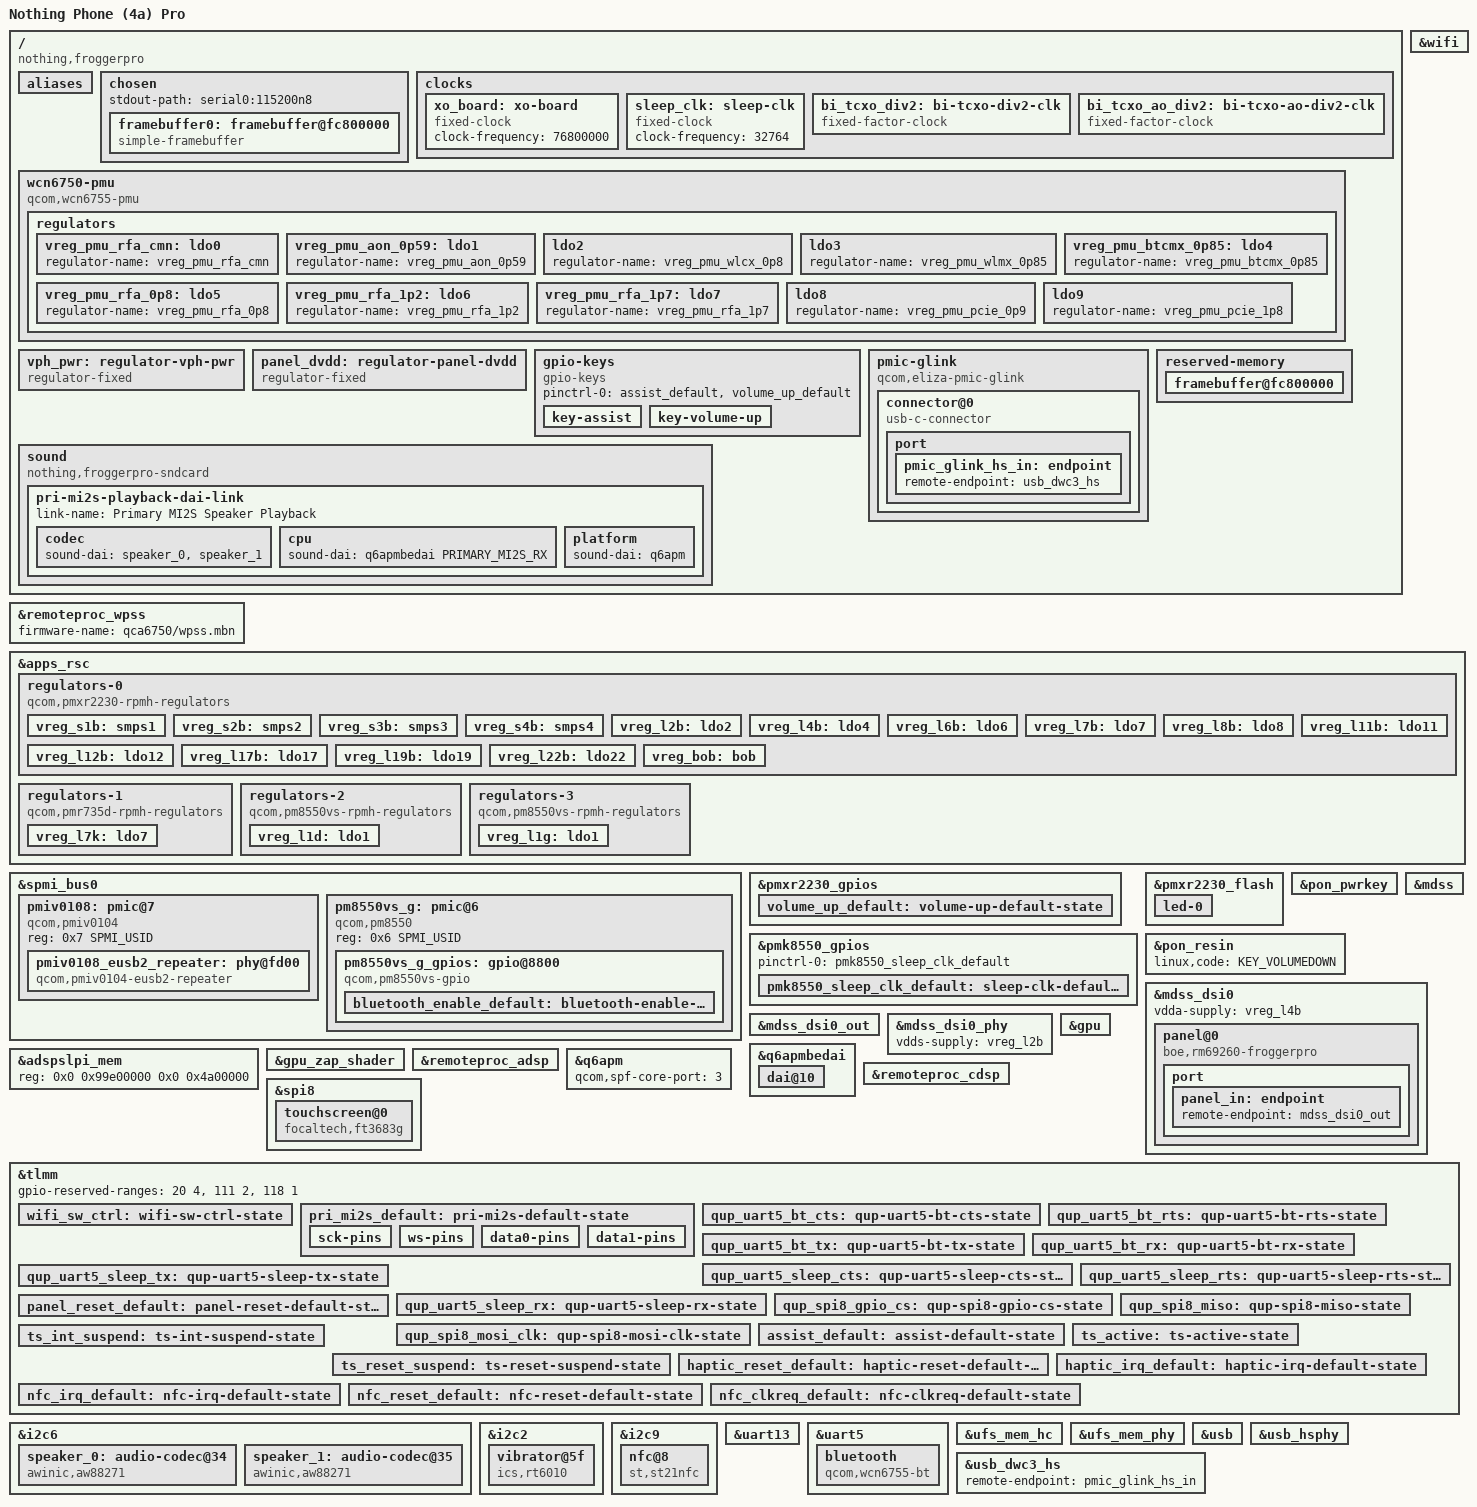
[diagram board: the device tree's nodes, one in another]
// SPDX-License-Identifier: BSD-3-Clause
/*
 * Copyright (c) 2026 Oleksii Onchul <oleksiionchul@gmail.com>
 */

/dts-v1/;

#include <dt-bindings/gpio/gpio.h>
#include <dt-bindings/input/input.h>
#include <dt-bindings/interrupt-controller/irq.h>
#include <dt-bindings/leds/common.h>
#include <dt-bindings/pinctrl/qcom,pmic-gpio.h>
#include <dt-bindings/regulator/qcom,rpmh-regulator.h>
#include <dt-bindings/spmi/spmi.h>

#include "eliza.dtsi"
#include "pmk8550-eliza.dtsi"
#include "pm8550vs-d-eliza.dtsi"
#include "pmr735d-eliza.dtsi"
#include "pmxr2230-eliza.dtsi"

/ {
	model = "Nothing Phone (4a) Pro";
	compatible = "nothing,froggerpro", "qcom,eliza";
	chassis-type = "handset";

	aliases {
		serial0 = &uart13;
		serial1 = &uart5;
	};

	chosen {
		#address-cells = <2>;
		#size-cells = <2>;
		ranges;

		stdout-path = "serial0:115200n8";

		framebuffer0: framebuffer@fc800000 {
			compatible = "simple-framebuffer";
			reg = <0x0 0xfc800000 0x0 (1260 * 2800 * 4)>;
			width = <1260>;
			height = <2800>;
			stride = <(1260 * 4)>;
			format = "a8r8g8b8";

			clocks = <&gcc GCC_DISP_HF_AXI_CLK>,
				 <&dispcc DISP_CC_MDSS_AHB_CLK>,
				 <&dispcc DISP_CC_MDSS_MDP_CLK>,
				 <&dispcc DISP_CC_MDSS_BYTE0_CLK>,
				 <&dispcc DISP_CC_MDSS_BYTE0_INTF_CLK>,
				 <&dispcc DISP_CC_MDSS_PCLK0_CLK>,
				 <&dispcc DISP_CC_MDSS_BYTE1_CLK>,
				 <&dispcc DISP_CC_MDSS_BYTE1_INTF_CLK>,
				 <&dispcc DISP_CC_MDSS_PCLK1_CLK>,
				 <&dispcc DISP_CC_MDSS_VSYNC_CLK>;
			power-domains = <&dispcc MDSS_GDSC>;
		};
	};

	clocks {
		xo_board: xo-board {
			compatible = "fixed-clock";
			clock-frequency = <76800000>;
			#clock-cells = <0>;
		};

		sleep_clk: sleep-clk {
			compatible = "fixed-clock";
			clock-frequency = <32764>;
			#clock-cells = <0>;
		};

		bi_tcxo_div2: bi-tcxo-div2-clk {
			compatible = "fixed-factor-clock";
			#clock-cells = <0>;

			clocks = <&rpmhcc RPMH_CXO_CLK>;
			clock-mult = <1>;
			clock-div = <2>;
		};

		bi_tcxo_ao_div2: bi-tcxo-ao-div2-clk {
			compatible = "fixed-factor-clock";
			#clock-cells = <0>;

			clocks = <&rpmhcc RPMH_CXO_CLK_A>;
			clock-mult = <1>;
			clock-div = <2>;
		};
	};

	wcn6750-pmu {
		compatible = "qcom,wcn6755-pmu", "qcom,wcn6750-pmu";

		vddaon-supply = <&vreg_s3b>;
		vddasd-supply = <&vreg_l7b>;
		vddio-supply = <&vreg_l11b>;
		vddpmu-supply = <&vreg_s3b>;
		vddrfa0p8-supply = <&vreg_s3b>;
		vddrfa1p2-supply = <&vreg_s2b>;
		vddrfa1p7-supply = <&vreg_s1b>;
		vddrfa2p2-supply = <&vreg_s4b>;

		bt-enable-gpios = <&pm8550vs_g_gpios 4 GPIO_ACTIVE_HIGH>;
		clocks = <&rpmhcc RPMH_RF_CLK1>;
		pinctrl-0 = <&bluetooth_enable_default>;
		pinctrl-names = "default";

		regulators {
			vreg_pmu_rfa_cmn: ldo0 {
				regulator-name = "vreg_pmu_rfa_cmn";
			};

			vreg_pmu_aon_0p59: ldo1 {
				regulator-name = "vreg_pmu_aon_0p59";
			};

			ldo2 {
				regulator-name = "vreg_pmu_wlcx_0p8";
			};

			ldo3 {
				regulator-name = "vreg_pmu_wlmx_0p85";
			};

			vreg_pmu_btcmx_0p85: ldo4 {
				regulator-name = "vreg_pmu_btcmx_0p85";
			};

			vreg_pmu_rfa_0p8: ldo5 {
				regulator-name = "vreg_pmu_rfa_0p8";
			};

			vreg_pmu_rfa_1p2: ldo6 {
				regulator-name = "vreg_pmu_rfa_1p2";
			};

			vreg_pmu_rfa_1p7: ldo7 {
				regulator-name = "vreg_pmu_rfa_1p7";
			};

			ldo8 {
				regulator-name = "vreg_pmu_pcie_0p9";
			};

			ldo9 {
				regulator-name = "vreg_pmu_pcie_1p8";
			};
		};
	};

	vph_pwr: regulator-vph-pwr {
		compatible = "regulator-fixed";
		regulator-name = "vph_pwr";
		regulator-min-microvolt = <3700000>;
		regulator-max-microvolt = <3700000>;

		regulator-always-on;
		regulator-boot-on;
	};

	panel_dvdd: regulator-panel-dvdd {
		compatible = "regulator-fixed";
		regulator-name = "panel_dvdd";
		regulator-min-microvolt = <1800000>;
		regulator-max-microvolt = <1800000>;
		gpio = <&tlmm 108 GPIO_ACTIVE_HIGH>;
		enable-active-high;
		regulator-boot-on;
	};

	gpio-keys {
		compatible = "gpio-keys";

		pinctrl-0 = <&assist_default>, <&volume_up_default>;
		pinctrl-names = "default";

		key-assist {
			gpios = <&tlmm 34 GPIO_ACTIVE_LOW>;
			label = "Assistant";
			linux,code = <KEY_LEFTMETA>;
		};

		key-volume-up {
			gpios = <&pmxr2230_gpios 6 GPIO_ACTIVE_LOW>;
			label = "Volume Up";
			linux,code = <KEY_VOLUMEUP>;
		};
	};

	pmic-glink {
		compatible = "qcom,eliza-pmic-glink",
			     "qcom,sm8550-pmic-glink",
			     "qcom,pmic-glink";
		#address-cells = <1>;
		#size-cells = <0>;

		connector@0 {
			compatible = "usb-c-connector";
			reg = <0>;
			data-role = "dual";
			power-role = "dual";

			port {
				pmic_glink_hs_in: endpoint {
					remote-endpoint = <&usb_dwc3_hs>;
				};
			};
		};
	};

	reserved-memory {
		framebuffer@fc800000 {
			reg = <0x0 0xfc800000 0x0 (1260 * 2800 * 4)>;
			no-map;
		};
	};

	sound {
		compatible = "nothing,froggerpro-sndcard", "qcom,sm8450-sndcard";
		model = "Nothing Phone (4a) Pro";
		pinctrl-0 = <&pri_mi2s_default>;
		pinctrl-names = "default";
		audio-routing = "Speaker 0", "Spkr0 OUT",
				"Speaker 1", "Spkr1 OUT";

		pri-mi2s-playback-dai-link {
			link-name = "Primary MI2S Speaker Playback";

			codec {
				sound-dai = <&speaker_0>, <&speaker_1>;
			};

			cpu {
				sound-dai = <&q6apmbedai PRIMARY_MI2S_RX>;
			};

			platform {
				sound-dai = <&q6apm>;
			};
		};
	};
};

&remoteproc_wpss {
	firmware-name = "qca6750/wpss.mbn";
	status = "okay";
};

&wifi {
	qcom,skip-cal-data;
	vdd-cx-mx-supply = <&vreg_s3b>;
	vdd-1.8-xo-supply = <&vreg_s1b>;
	vdd-1.3-rfa-supply = <&vreg_s2b>;
	vdd-1.8-io-supply = <&vreg_l11b>;
	pinctrl-0 = <&wifi_sw_ctrl>;
	pinctrl-names = "default";
	status = "okay";
};

&apps_rsc {
	regulators-0 {
		compatible = "qcom,pmxr2230-rpmh-regulators";

		vdd-s1-supply = <&vph_pwr>;
		vdd-s2-supply = <&vph_pwr>;
		vdd-s3-supply = <&vph_pwr>;
		vdd-s4-supply = <&vph_pwr>;
		vdd-l4-l5-supply = <&vreg_s2b>;
		vdd-l6-supply = <&vreg_s2b>;
		vdd-l7-supply = <&vreg_s1b>;
		vdd-l11-supply = <&vreg_s1b>;
		vdd-l12-l14-supply = <&vreg_bob>;
		vdd-l15-l17-l18-l19-l20-l21-l22-l23-supply = <&vreg_bob>;
		vdd-bob-supply = <&vph_pwr>;

		qcom,pmic-id = "b";

		vreg_s1b: smps1 {
			regulator-name = "vreg_s1b";
			regulator-min-microvolt = <1856000>;
			regulator-max-microvolt = <2040000>;
			regulator-initial-mode = <RPMH_REGULATOR_MODE_HPM>;
		};

		vreg_s2b: smps2 {
			regulator-name = "vreg_s2b";
			regulator-min-microvolt = <1256000>;
			regulator-max-microvolt = <1408000>;
			regulator-initial-mode = <RPMH_REGULATOR_MODE_HPM>;
		};

		vreg_s3b: smps3 {
			regulator-name = "vreg_s3b";
			regulator-min-microvolt = <880000>;
			regulator-max-microvolt = <1040000>;
			regulator-initial-mode = <RPMH_REGULATOR_MODE_HPM>;
		};

		vreg_s4b: smps4 {
			regulator-name = "vreg_s4b";
			regulator-min-microvolt = <2156000>;
			regulator-max-microvolt = <2600000>;
			regulator-initial-mode = <RPMH_REGULATOR_MODE_HPM>;
		};

		vreg_l2b: ldo2 {
			regulator-name = "vreg_l2b";
			regulator-min-microvolt = <720000>;
			regulator-max-microvolt = <950000>;
			regulator-initial-mode = <RPMH_REGULATOR_MODE_HPM>;
		};

		vreg_l4b: ldo4 {
			regulator-name = "vreg_l4b";
			regulator-min-microvolt = <1080000>;
			regulator-max-microvolt = <1320000>;
			regulator-initial-mode = <RPMH_REGULATOR_MODE_HPM>;
		};

		vreg_l6b: ldo6 {
			regulator-name = "vreg_l6b";
			regulator-min-microvolt = <866000>;
			regulator-max-microvolt = <958000>;
			regulator-initial-mode = <RPMH_REGULATOR_MODE_HPM>;
		};

		vreg_l7b: ldo7 {
			regulator-name = "vreg_l7b";
			regulator-min-microvolt = <1800000>;
			regulator-max-microvolt = <2000000>;
			regulator-initial-mode = <RPMH_REGULATOR_MODE_HPM>;
		};

		vreg_l8b: ldo8 {
			regulator-name = "vreg_l8b";
			regulator-min-microvolt = <1800000>;
			regulator-max-microvolt = <1800000>;
			regulator-initial-mode = <RPMH_REGULATOR_MODE_HPM>;
			regulator-boot-on;
			regulator-always-on;
		};

		vreg_l11b: ldo11 {
			regulator-name = "vreg_l11b";
			regulator-min-microvolt = <1800000>;
			regulator-max-microvolt = <1800000>;
			regulator-initial-mode = <RPMH_REGULATOR_MODE_HPM>;
		};

		vreg_l12b: ldo12 {
			regulator-name = "vreg_l12b";
			regulator-min-microvolt = <2400000>;
			regulator-max-microvolt = <3300000>;
			regulator-initial-mode = <RPMH_REGULATOR_MODE_HPM>;
		};

		vreg_l17b: ldo17 {
			regulator-name = "vreg_l17b";
			regulator-min-microvolt = <2700000>;
			regulator-max-microvolt = <3544000>;
			regulator-initial-mode = <RPMH_REGULATOR_MODE_HPM>;
		};

		vreg_l19b: ldo19 {
			regulator-name = "vreg_l19b";
			regulator-min-microvolt = <3000000>;
			regulator-max-microvolt = <3000000>;
			regulator-initial-mode = <RPMH_REGULATOR_MODE_HPM>;
			regulator-boot-on;
		};

		vreg_l22b: ldo22 {
			regulator-name = "vreg_l22b";
			regulator-min-microvolt = <3200000>;
			regulator-max-microvolt = <3200000>;
			regulator-initial-mode = <RPMH_REGULATOR_MODE_HPM>;
		};

		vreg_bob: bob {
			regulator-name = "vreg_bob";
			regulator-min-microvolt = <3296000>;
			regulator-max-microvolt = <3960000>;
			regulator-initial-mode = <RPMH_REGULATOR_MODE_HPM>;
			regulator-boot-on;
		};
	};

	regulators-1 {
		compatible = "qcom,pmr735d-rpmh-regulators";

		vdd-l7-supply = <&vreg_s3b>;

		qcom,pmic-id = "k";

		vreg_l7k: ldo7 {
			regulator-name = "vreg_l7k";
			regulator-min-microvolt = <720000>;
			regulator-max-microvolt = <958000>;
			regulator-initial-mode = <RPMH_REGULATOR_MODE_HPM>;
		};
	};

	regulators-2 {
		compatible = "qcom,pm8550vs-rpmh-regulators";

		vdd-l1-supply = <&vreg_s2b>;

		qcom,pmic-id = "d";

		vreg_l1d: ldo1 {
			regulator-name = "vreg_l1d";
			regulator-min-microvolt = <1140000>;
			regulator-max-microvolt = <1260000>;
			regulator-initial-mode = <RPMH_REGULATOR_MODE_HPM>;
		};
	};

	regulators-3 {
		compatible = "qcom,pm8550vs-rpmh-regulators";

		vdd-l1-supply = <&vreg_s2b>;

		qcom,pmic-id = "g";

		vreg_l1g: ldo1 {
			regulator-name = "vreg_l1g";
			/* Stock FocalTech driver requests 1.8 V on this rail. */
			regulator-min-microvolt = <1800000>;
			regulator-max-microvolt = <1800000>;
			regulator-initial-mode = <RPMH_REGULATOR_MODE_HPM>;
		};
	};
};

&spmi_bus0 {
	pmiv0108: pmic@7 {
		compatible = "qcom,pmiv0104", "qcom,spmi-pmic";
		reg = <0x7 SPMI_USID>;
		#address-cells = <1>;
		#size-cells = <0>;

		pmiv0108_eusb2_repeater: phy@fd00 {
			compatible = "qcom,pmiv0104-eusb2-repeater";
			reg = <0xfd00>;
			#phy-cells = <0>;

			vdd18-supply = <&vreg_l7b>;
			vdd3-supply = <&vreg_l17b>;

			qcom,tune-usb2-amplitude = /bits/ 8 <0xd>;
			qcom,tune-usb2-preem = /bits/ 8 <0x7>;
			qcom,squelch-detector-bp = <(-2000)>;
		};
	};
};

&pmxr2230_gpios {
	volume_up_default: volume-up-default-state {
		pins = "gpio6";
		function = PMIC_GPIO_FUNC_NORMAL;
		power-source = <1>;
		bias-pull-up;
	};
};

&pmk8550_gpios {
	pinctrl-0 = <&pmk8550_sleep_clk_default>;
	pinctrl-names = "default";

	pmk8550_sleep_clk_default: sleep-clk-default-state {
		pins = "gpio3";
		function = PMIC_GPIO_FUNC_FUNC1;
		input-disable;
		output-enable;
		bias-disable;
		power-source = <0>;
	};
};

&spmi_bus0 {
	pm8550vs_g: pmic@6 {
		compatible = "qcom,pm8550", "qcom,spmi-pmic";
		reg = <0x6 SPMI_USID>;
		#address-cells = <1>;
		#size-cells = <0>;

		pm8550vs_g_gpios: gpio@8800 {
			compatible = "qcom,pm8550vs-gpio", "qcom,spmi-gpio";
			reg = <0x8800>;
			gpio-controller;
			gpio-ranges = <&pm8550vs_g_gpios 0 0 6>;
			#gpio-cells = <2>;
			interrupt-controller;
			#interrupt-cells = <2>;

			bluetooth_enable_default: bluetooth-enable-default-state {
				pins = "gpio4";
				function = PMIC_GPIO_FUNC_NORMAL;
				input-disable;
				output-enable;
				bias-disable;
				power-source = <1>;
			};
		};
	};
};

&pmxr2230_flash {
	status = "okay";

	/* The working torch is connected to outputs 1 and 4. */
	led-0 {
		function = LED_FUNCTION_FLASH;
		color = <LED_COLOR_ID_WHITE>;
		led-sources = <1>, <4>;
		led-max-microamp = <110000>;
		flash-max-microamp = <1500000>;
		flash-max-timeout-us = <1280000>;
		function-enumerator = <0>;
	};
};

&pon_pwrkey {
	status = "okay";
};

&pon_resin {
	linux,code = <KEY_VOLUMEDOWN>;

	status = "okay";
};

&mdss {
	status = "okay";
};

&mdss_dsi0 {
	vdda-supply = <&vreg_l4b>;

	status = "okay";

	panel@0 {
		compatible = "boe,rm69260-froggerpro";
		reg = <0>;

		vddio-supply = <&vreg_l8b>;
		dvdd-supply = <&panel_dvdd>;
		vci-supply = <&vreg_l19b>;
		reset-gpios = <&tlmm 12 GPIO_ACTIVE_LOW>;

		pinctrl-0 = <&panel_reset_default>;
		pinctrl-names = "default";

		port {
			panel_in: endpoint {
				remote-endpoint = <&mdss_dsi0_out>;
			};
		};
	};
};

&mdss_dsi0_out {
	data-lanes = <0 1 2 3>;
	remote-endpoint = <&panel_in>;
};

&mdss_dsi0_phy {
	vdds-supply = <&vreg_l2b>;

	status = "okay";
};

&adspslpi_mem {
	reg = <0x0 0x99e00000 0x0 0x4a00000>;
};

&gpu {
	status = "okay";
};

&gpu_zap_shader {
	firmware-name = "qcom/sm7750/nothing/froggerpro/gen70e00_zap.mbn";
};

&remoteproc_adsp {
	firmware-name = "qcom/sm7750/nothing/froggerpro/adsp.mbn",
			"qcom/sm7750/nothing/froggerpro/adsp_dtb.mbn";

	status = "okay";
};

&q6apm {
	qcom,spf-core-port = <3>;
};

&q6apmbedai {
	#address-cells = <1>;
	#size-cells = <0>;

	dai@10 {
		reg = <PRIMARY_MI2S_RX>;
		clocks = <&q6prmcc LPASS_CLK_ID_PRI_MI2S_IBIT
				 LPASS_CLK_ATTRIBUTE_COUPLE_NO>;
		clock-names = "bclk";
	};
};

&remoteproc_cdsp {
	firmware-name = "qcom/sm7750/nothing/froggerpro/cdsp.mbn",
			"qcom/sm7750/nothing/froggerpro/cdsp_dtb.mbn";

	status = "okay";
};

&spi8 {
	status = "okay";
	cs-gpios = <&tlmm 3 GPIO_ACTIVE_LOW>;
	pinctrl-0 = <&qup_spi8_miso>, <&qup_spi8_mosi_clk>,
		    <&qup_spi8_gpio_cs>;

	touchscreen@0 {
		compatible = "focaltech,ft3683g";
		reg = <0>;
		spi-max-frequency = <1000000>;

		interrupt-parent = <&tlmm>;
		interrupts = <13 IRQ_TYPE_LEVEL_LOW>;
		reset-gpios = <&tlmm 16 GPIO_ACTIVE_LOW>;

		vdd-supply = <&vreg_l22b>;
		iovcc-supply = <&vreg_l1g>;
		touchscreen-size-x = <1260>;
		touchscreen-size-y = <2800>;

		pinctrl-0 = <&ts_active>;
		pinctrl-1 = <&ts_int_suspend>, <&ts_reset_suspend>;
		pinctrl-names = "default", "sleep";
	};
};

&tlmm {
	gpio-reserved-ranges = <20 4>,   /* NFC SPI */
			       <111 2>,  /* WCN UART1 */
			       <118 1>;  /* NFC Secure I/O */

	wifi_sw_ctrl: wifi-sw-ctrl-state {
		pins = "gpio81";
		function = "wcn_sw_ctrl";
	};

	pri_mi2s_default: pri-mi2s-default-state {
		sck-pins {
			pins = "gpio60";
			function = "i2s0_sck";
			drive-strength = <8>;
			bias-disable;
		};

		ws-pins {
			pins = "gpio61";
			function = "i2s0_ws";
			drive-strength = <8>;
			bias-disable;
		};

		data0-pins {
			pins = "gpio64";
			function = "i2s0_data0";
			drive-strength = <8>;
			bias-disable;
		};

		data1-pins {
			pins = "gpio63";
			function = "i2s0_data1";
			drive-strength = <8>;
			bias-pull-down;
		};
	};

	qup_uart5_bt_cts: qup-uart5-bt-cts-state {
		pins = "gpio132";
		function = "qup1_se5";
		bias-bus-hold;
	};

	qup_uart5_bt_rts: qup-uart5-bt-rts-state {
		pins = "gpio133";
		function = "qup1_se5";
		drive-strength = <2>;
		bias-disable;
	};

	qup_uart5_bt_tx: qup-uart5-bt-tx-state {
		pins = "gpio134";
		function = "qup1_se5";
		drive-strength = <2>;
		bias-disable;
	};

	qup_uart5_bt_rx: qup-uart5-bt-rx-state {
		pins = "gpio135";
		function = "qup1_se5";
		bias-pull-up;
	};

	qup_uart5_sleep_cts: qup-uart5-sleep-cts-state {
		pins = "gpio132";
		function = "gpio";
		bias-bus-hold;
	};

	qup_uart5_sleep_rts: qup-uart5-sleep-rts-state {
		pins = "gpio133";
		function = "gpio";
		bias-pull-down;
	};

	qup_uart5_sleep_tx: qup-uart5-sleep-tx-state {
		pins = "gpio134";
		function = "gpio";
		bias-pull-up;
	};

	qup_uart5_sleep_rx: qup-uart5-sleep-rx-state {
		pins = "gpio135";
		function = "gpio";
		bias-pull-up;
	};

	qup_spi8_gpio_cs: qup-spi8-gpio-cs-state {
		pins = "gpio3";
		function = "gpio";
		drive-strength = <6>;
		bias-disable;
		output-high;
	};

	panel_reset_default: panel-reset-default-state {
		pins = "gpio12";
		function = "gpio";
		drive-strength = <8>;
		bias-disable;
	};

	qup_spi8_miso: qup-spi8-miso-state {
		pins = "gpio0";
		function = "qup2_se0";
		drive-strength = <6>;
		bias-disable;
		input-enable;
	};

	qup_spi8_mosi_clk: qup-spi8-mosi-clk-state {
		pins = "gpio1", "gpio2";
		function = "qup2_se0";
		drive-strength = <6>;
		bias-disable;
	};

	assist_default: assist-default-state {
		pins = "gpio34";
		function = "gpio";
		bias-pull-up;
	};

	ts_active: ts-active-state {
		pins = "gpio13", "gpio16";
		function = "gpio";
		drive-strength = <8>;
		bias-pull-up;
	};

	ts_int_suspend: ts-int-suspend-state {
		pins = "gpio13";
		function = "gpio";
		drive-strength = <2>;
		bias-pull-down;
	};

	ts_reset_suspend: ts-reset-suspend-state {
		pins = "gpio16";
		function = "gpio";
		drive-strength = <2>;
		bias-pull-down;
	};

	haptic_reset_default: haptic-reset-default-state {
		pins = "gpio30";
		function = "gpio";
		drive-strength = <2>;
		bias-disable;
	};

	haptic_irq_default: haptic-irq-default-state {
		pins = "gpio116";
		function = "gpio";
		bias-pull-up;
		input-enable;
	};

	nfc_irq_default: nfc-irq-default-state {
		pins = "gpio7";
		function = "gpio";
		bias-pull-down;
		input-enable;
	};

	nfc_reset_default: nfc-reset-default-state {
		pins = "gpio57";
		function = "gpio";
		bias-disable;
	};

	nfc_clkreq_default: nfc-clkreq-default-state {
		pins = "gpio6";
		function = "gpio";
		bias-disable;
		input-enable;
	};
};

&i2c6 {
	status = "okay";

	speaker_0: audio-codec@34 {
		compatible = "awinic,aw88271";
		reg = <0x34>;
		#sound-dai-cells = <0>;
		reset-gpios = <&tlmm 146 GPIO_ACTIVE_LOW>;
		sound-name-prefix = "Spkr0";
		awinic,audio-channel = <0>;
		firmware-name = "aw882xx_acf.bin";
	};

	speaker_1: audio-codec@35 {
		compatible = "awinic,aw88271";
		reg = <0x35>;
		#sound-dai-cells = <0>;
		reset-gpios = <&tlmm 147 GPIO_ACTIVE_LOW>;
		sound-name-prefix = "Spkr1";
		awinic,audio-channel = <1>;
		firmware-name = "aw882xx_acf.bin";
	};
};

&i2c2 {
	status = "okay";

	vibrator@5f {
		compatible = "ics,rt6010";
		reg = <0x5f>;
		reset-gpios = <&tlmm 30 GPIO_ACTIVE_LOW>;
		interrupts-extended = <&tlmm 116 IRQ_TYPE_LEVEL_LOW>;
		pinctrl-0 = <&haptic_reset_default>, <&haptic_irq_default>;
		pinctrl-names = "default";
	};
};

&i2c9 {
	status = "okay";

	nfc@8 {
		compatible = "st,st21nfc";
		reg = <0x08>;
		interrupts-extended = <&tlmm 7 IRQ_TYPE_LEVEL_HIGH>;
		reset-gpios = <&tlmm 57 GPIO_ACTIVE_LOW>;
		clkreq-gpios = <&tlmm 6 GPIO_ACTIVE_HIGH>;
		pinctrl-0 = <&nfc_irq_default>, <&nfc_reset_default>,
			    <&nfc_clkreq_default>;
		pinctrl-names = "default";
	};
};

/* UART_RX and UART_TX are routed to test points on the board. */
&uart13 {
	status = "okay";
};

&uart5 {
	/delete-property/ interrupts;
	interrupts-extended = <&intc GIC_SPI 358 IRQ_TYPE_LEVEL_HIGH>,
			      <&tlmm 135 IRQ_TYPE_EDGE_FALLING>;

	pinctrl-0 = <&qup_uart5_bt_cts>, <&qup_uart5_bt_rts>,
		    <&qup_uart5_bt_tx>, <&qup_uart5_bt_rx>;
	pinctrl-1 = <&qup_uart5_sleep_cts>, <&qup_uart5_sleep_rts>,
		    <&qup_uart5_sleep_tx>, <&qup_uart5_sleep_rx>;
	pinctrl-names = "default", "sleep";

	status = "okay";

	bluetooth {
		compatible = "qcom,wcn6755-bt", "qcom,wcn6750-bt";

		vddaon-supply = <&vreg_pmu_aon_0p59>;
		vddbtcmx-supply = <&vreg_pmu_btcmx_0p85>;
		vddrfa0p8-supply = <&vreg_pmu_rfa_0p8>;
		vddrfa1p2-supply = <&vreg_pmu_rfa_1p2>;
		vddrfa1p7-supply = <&vreg_pmu_rfa_1p7>;
		vddrfacmn-supply = <&vreg_pmu_rfa_cmn>;
	};
};

&ufs_mem_hc {
	reset-gpios = <&tlmm 185 GPIO_ACTIVE_LOW>;

	vcc-supply = <&vreg_l12b>;
	vcc-max-microamp = <1300000>;
	vccq-supply = <&vreg_l1d>;
	vccq-max-microamp = <1200000>;

	status = "okay";
};

&ufs_mem_phy {
	vdda-phy-supply = <&vreg_l6b>;
	vdda-pll-supply = <&vreg_l4b>;

	status = "okay";
};

&usb {
	/* USB 2.0 only, the board does not route the SuperSpeed lanes. */
	dr_mode = "otg";
	maximum-speed = "high-speed";
	phys = <&usb_hsphy>;
	phy-names = "usb2-phy";
	qcom,select-utmi-as-pipe-clk;

	status = "okay";
};

&usb_dwc3_hs {
	remote-endpoint = <&pmic_glink_hs_in>;
};

&usb_hsphy {
	vdd-supply = <&vreg_l7k>;
	vdda12-supply = <&vreg_l4b>;

	phys = <&pmiv0108_eusb2_repeater>;

	status = "okay";
};
